# C7X256V_DEBUG_C7X256V_DEBUG_DBG_AGR0_MMR_000734040000h register map
Vendor: Texas Instruments
Peripheral module from a debugger description file (folder AM275x).
Registers are 32-bit, access per field, reset values left out (the file's numbers can be read two ways) unless marked. A register's access mark holds for its fields unless they carry their own. Offsets are as the file gives them; lines under a group give offsets from that group; [hi:lo] are bit positions; {n}, {i} and the like mark numbered series; 'fields as' and 'values as' point back to an identical list; <NAME> marks a mode.

## C7X256V_DEBUG_DBG_AGR0_MMR
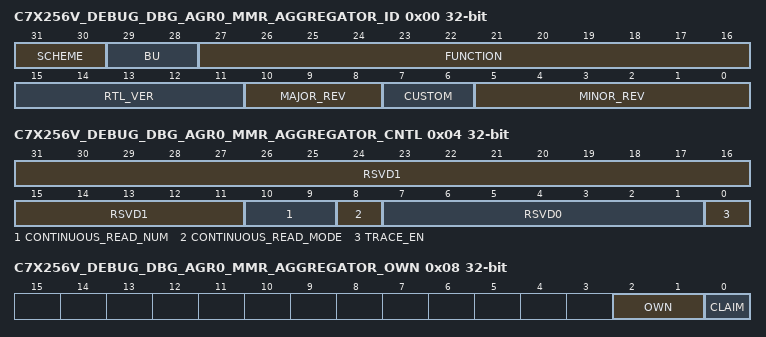
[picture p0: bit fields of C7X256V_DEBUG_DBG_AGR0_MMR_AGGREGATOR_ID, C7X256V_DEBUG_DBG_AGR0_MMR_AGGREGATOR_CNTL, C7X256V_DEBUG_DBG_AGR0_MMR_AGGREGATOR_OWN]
0x00 C7X256V_DEBUG_DBG_AGR0_MMR_AGGREGATOR_ID ro — This is the standard TI peripheral ID register that exists at address 0 in the preipheral space
  [31:30] SCHEME — scheme Reset Source: cfg_rst_n
  [29:28] BU — Business Unit Reset Source: cfg_rst_n
  [27:16] FUNCTION — function Reset Source: cfg_rst_n
  [15:11] RTL_VER — rtl_ver Reset Source: cfg_rst_n
  [10:8] MAJOR_REV — major_rev Reset Source: cfg_rst_n
  [7:6] CUSTOM — custom Reset Source: cfg_rst_n
  [5:0] MINOR_REV — minor_rev Reset Source: cfg_rst_n
0x04 C7X256V_DEBUG_DBG_AGR0_MMR_AGGREGATOR_CNTL — This register contains the controls for serial indrect access and trace processing
  [31:11] RSVD1 ro — rsvd1 Reset Source: cfg_rst_n
  [10:9] CONTINUOUS_READ_NUM rw — continuous read num Reset Source: cfg_rst_n
  [8] CONTINUOUS_READ_MODE rw — continuous read mode Reset Source: cfg_rst_n
  [7:1] RSVD0 ro — rsvd0 Reset Source: cfg_rst_n
  [0] TRACE_EN rw — trace enable Reset Source: cfg_rst_n
0x08 C7X256V_DEBUG_DBG_AGR0_MMR_AGGREGATOR_OWN — Module Ownership Control and Status Register
  [2:1] OWN ro — own status bit Reset Source: cfg_rst_n
  [0] CLAIM rw — claim control bit Reset Source: cfg_rst_n
{0x20+0x10*i} C7X256V_DEBUG_DBG_AGR0_MMR_CONT_READ_PORT{i} (i=0..3) — Designates which port (peripheral) is the target of this port, address, data register group
  [4:0] PORT rw — port {i} Reset Source: cfg_rst_n
{0x24+0x10*i} C7X256V_DEBUG_DBG_AGR0_MMR_CONT_READ_ADDR{i} (i=0..3) — Designates the offest (in peripheral space) that is the target of this port, address, data register group
  [15:0] ADDR rw — The 16-bit address of the target destination in the address space of the targeted peripheral. This is essentially the offset of the target in the peripheral space. Reset Source: cfg_rst_n
{0x28+0x10*i} C7X256V_DEBUG_DBG_AGR0_MMR_CONT_READ_DATA{i} ro (i=0..3) — Provides the continuous read data for this port, address, data register group
  [31:0] DATA — The read data for the serially accessed register Reset Source: cfg_rst_n
